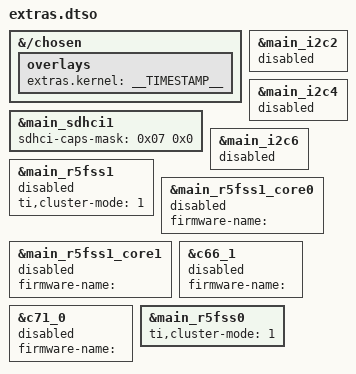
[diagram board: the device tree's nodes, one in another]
/dts-v1/;
/plugin/;

&{/chosen} {
	overlays {
		extras.kernel = __TIMESTAMP__;
	};
};


// &{/reserved-memory} {
// 	ipc_mem@aa000000 {
// 		reg = <0x0 0xaa000000 0x0 0x01000000>;  /* 16 MiB */
// 		no-map;
// 	};

// 	vision-tele@ab000000 {
// 		reg = <0x0 0xab000000 0x0 0x00800000>;  /* 8 MiB */
// 		no-map;
// 	};
// };

&main_sdhci1 {
    sdhci-caps-mask = <0x07 0x0>;
};

&main_i2c2 {
	status = "disabled";
};

&main_i2c4 {
	status = "disabled";
};

&main_i2c6 {
	status = "disabled";
};

&main_r5fss1 {
    /* 1 = lockstep, 0 = split */
	status = "disabled";
    ti,cluster-mode = <1>;
};

/* disable only the entry core in lockstep */
&main_r5fss1_core0 {
    status = "disabled";
    firmware-name = "";
};

/* Core1 is unused in lockstep but we disable it just in case */
&main_r5fss1_core1 {
    status = "disabled";
    firmware-name = "";
};

&c66_1 {
	status = "disabled";
	firmware-name = "";
};

&c71_0 {
	status = "disabled";
	firmware-name = "";
};

// &main_uart0 {
// 	status = "disabled";
// };

&main_r5fss0 {
    ti,cluster-mode = <1>;	// lockstep
};
